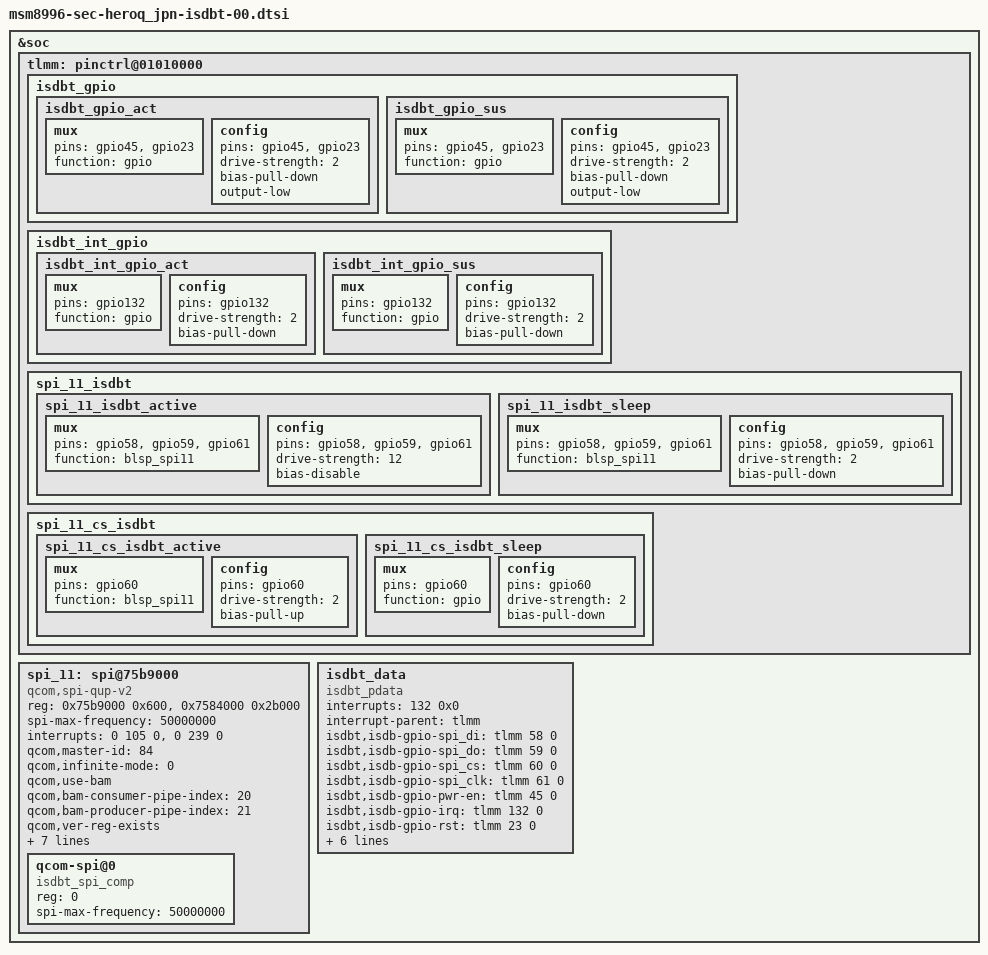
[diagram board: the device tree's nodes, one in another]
 /*
 * This program is free software; you can redistribute it and/or modify
 * it under the terms of the GNU General Public License version 2 and
 * only version 2 as published by the Free Software Foundation.
 *
 * This program is distributed in the hope that it will be useful,
 * but WITHOUT ANY WARRANTY; without even the implied warranty of
 * MERCHANTABILITY or FITNESS FOR A PARTICULAR PURPOSE.  See the
 * GNU General Public License for more details.
 */



&soc {
	tlmm: pinctrl@01010000 {
		isdbt_gpio {
			isdbt_gpio_act: isdbt_gpio_act {
				mux {
					pins = "gpio45", "gpio23";
					function = "gpio";
				};

				config {
					pins = "gpio45", "gpio23";
					drive-strength = <2>;
					bias-pull-down; /* PULL DOWN */
					output-low;
				};
			};
			isdbt_gpio_sus: isdbt_gpio_sus {
				mux {
					pins = "gpio45", "gpio23";
					function = "gpio";
				};

				config {
					pins = "gpio45", "gpio23";
					drive-strength = <2>;
					bias-pull-down; /* PULL DOWN */
					output-low;
				};
			};

		};

		isdbt_int_gpio {
        		isdbt_int_gpio_act: isdbt_int_gpio_act {
				mux {
					pins = "gpio132";
					function = "gpio";
				};

				config {
					pins = "gpio132";
					drive-strength = <2>;
					bias-pull-down; /* PULL DOWN */
				};
			};
			isdbt_int_gpio_sus: isdbt_int_gpio_sus {
				mux {
					pins = "gpio132";
					function = "gpio";
				};

				config {
					pins = "gpio132";
					drive-strength = <2>;
					bias-pull-down; /* PULL DOWN */
				};
			};
		};

		spi_11_isdbt {
			spi_11_isdbt_active: spi_11_isdbt_active {
				mux {
					pins = "gpio58", "gpio59", "gpio61";
					function = "blsp_spi11";
				};
	
				config {
					pins = "gpio58", "gpio59", "gpio61";
					drive-strength = <12>;
					bias-disable;
				};
			};
	
			spi_11_isdbt_sleep: spi_11_isdbt_sleep {
				mux {
					pins = "gpio58", "gpio59", "gpio61";
					function = "blsp_spi11";
				};
	
				config {
					pins = "gpio58", "gpio59", "gpio61";
					drive-strength = <2>;
					bias-pull-down;
				};
			};
		};
	
		spi_11_cs_isdbt {
			spi_11_cs_isdbt_active: spi_11_cs_isdbt_active {
				mux {
					pins = "gpio60";
					function = "blsp_spi11";
				};
	
				config {
					pins = "gpio60";
					drive-strength = <2>;
					bias-pull-up;
				};
			};
	
			spi_11_cs_isdbt_sleep: spi_11_cs_isdbt_sleep {
				mux {
					pins = "gpio60";
					function = "gpio";
				};
	
				config {
					pins = "gpio60";
					drive-strength = <2>;
					bias-pull-down;
				};
			};
		};
	};


	/delete-node/ spi@75b9000;
	spi_11: spi@75b9000 { /* BLSP2 QUP4 */
		compatible = "qcom,spi-qup-v2";
		#address-cells = <1>;
		#size-cells = <0>;
		reg-names = "spi_physical", "spi_bam_physical";
		reg = <0x75b9000 0x600>, <0x7584000 0x2b000>;
		spi-max-frequency = <50000000>;
		interrupt-names = "spi_irq", "spi_bam_irq";
		interrupts = <0 105 0>, <0 239 0>;
		qcom,master-id = <84>;

		qcom,infinite-mode = <0>;
		qcom,use-bam;
		qcom,bam-consumer-pipe-index = <20>;
		qcom,bam-producer-pipe-index = <21>;

		status = "ok";

		qcom,ver-reg-exists;
		qcom,use-pinctrl;
		pinctrl-names = "spi_default", "spi_sleep";
		pinctrl-0 = <&spi_11_isdbt_active &spi_11_cs_isdbt_active>;
		pinctrl-1 = <&spi_11_isdbt_sleep &spi_11_cs_isdbt_sleep>;

		clock-names = "iface_clk", "core_clk";

		clocks = <&clock_gcc clk_gcc_blsp2_ahb_clk>,
		       <&clock_gcc clk_gcc_blsp2_qup5_spi_apps_clk>;
		qcom-spi@0 {
			compatible = "isdbt_spi_comp";
			reg = <0>;
			spi-max-frequency = <50000000>;
		};
	};

	isdbt_data {
		compatible = "isdbt_pdata";
		interrupts = <132 0x0>;
		interrupt-parent = <&tlmm>;

		isdbt,isdb-gpio-spi_di = <&tlmm 58 0>;
		isdbt,isdb-gpio-spi_do = <&tlmm 59 0>;
		isdbt,isdb-gpio-spi_cs = <&tlmm 60 0>;
		isdbt,isdb-gpio-spi_clk = <&tlmm 61 0>;
		
		isdbt,isdb-gpio-pwr-en = <&tlmm 45 0>;
		isdbt,isdb-gpio-irq = <&tlmm 132 0>;
		isdbt,isdb-gpio-rst = <&tlmm 23 0>;

		isdbt,ldo_vdd_1p8 = "pm8994_l29";

		isdbt,isdb-bbm-xtal-freq = <19200>;
		clocks = <&clock_gcc clk_bb_clk2>;
		qcom,clk-src = "BBCLK2";
		clock-names = "isdbt_clkout";

		pinctrl-names = "isdbt_gpio_active", "isdbt_gpio_suspend";
		pinctrl-0 = <&isdbt_gpio_act &isdbt_int_gpio_act>;
		pinctrl-1 = <&isdbt_gpio_sus &isdbt_int_gpio_sus>;
	};

};

